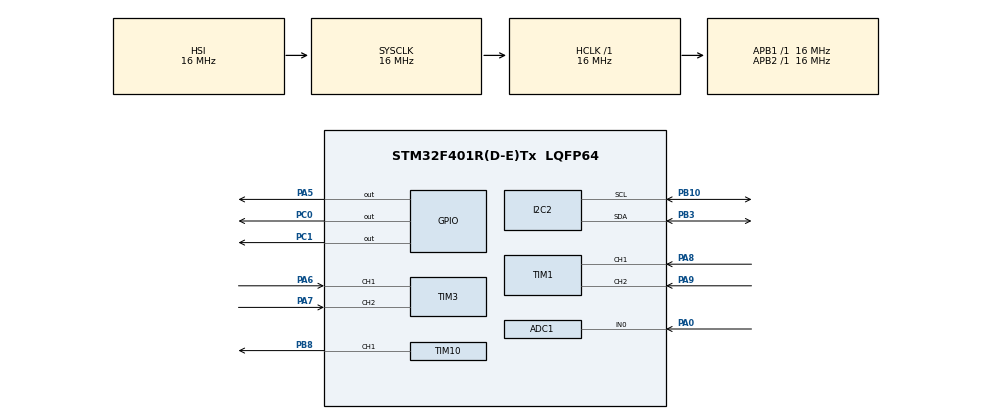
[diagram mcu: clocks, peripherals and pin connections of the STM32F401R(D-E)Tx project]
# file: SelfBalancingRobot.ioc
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Mcu.Family=STM32F4
TIM10.Prescaler=14
Dma.ADC1.0.Instance=DMA2_Stream0
RCC.CortexFreq_Value=16000000
ADC1.Rank-0\#ChannelRegularConversion=1
PB10.Mode=I2C
TIM11.Prescaler=9
PC0.Signal=GPIO_Output
ProjectManager.StackSize=0x400
PA0-WKUP.Signal=ADCx_IN0
VP_TIM11_VS_ClockSourceINT.Mode=Enable_Timer
Dma.ADC1.0.PeriphDataAlignment=DMA_PDATAALIGN_HALFWORD
SH.S_TIM1_CH1.0=TIM1_CH1,Encoder_Interface
ProjectManager.TargetToolchain=STM32CubeIDE
Dma.ADC1.0.Mode=DMA_CIRCULAR
ADC1.Resolution=ADC_RESOLUTION_8B
Dma.ADC1.0.Priority=DMA_PRIORITY_LOW
PA9.Signal=S_TIM1_CH2
VP_TIM10_VS_ClockSourceINT.Mode=Enable_Timer
Dma.ADC1.0.Direction=DMA_PERIPH_TO_MEMORY
NVIC.DMA2_Stream0_IRQn=true\:0\:0\:false\:false\:true\:false\:true
RCC.LSE_VALUE=32768
Dma.ADC1.0.MemDataAlignment=DMA_MDATAALIGN_HALFWORD
RCC.AHBFreq_Value=16000000
PB10.Signal=I2C2_SCL
PA5.Signal=GPIO_Output
ADC1.Channel-0\#ChannelRegularConversion=ADC_CHANNEL_0
SH.S_TIM3_CH2.0=TIM3_CH2,Encoder_Interface
NVIC.TIM1_TRG_COM_TIM11_IRQn=true\:0\:0\:false\:false\:true\:true\:true
RCC.HSE_VALUE=25000000
PB3.Mode=I2C
board=custom
RCC.VCOOutputFreq_Value=192000000
TIM10.Channel=TIM_CHANNEL_1
TIM11.Period=15999
TIM10.Period=99
RCC.APB2Freq_Value=16000000
SH.S_TIM1_CH2.0=TIM1_CH2,Encoder_Interface
Dma.ADC1.0.PeriphInc=DMA_PINC_DISABLE
PA8.Signal=S_TIM1_CH1
SH.ADCx_IN0.0=ADC1_IN0,IN0
SH.S_TIM3_CH1.0=TIM3_CH1,Encoder_Interface
ADC1.DMAContinuousRequests=ENABLE
Mcu.Name=STM32F401R(D-E)Tx
ADC1.SamplingTime-0\#ChannelRegularConversion=ADC_SAMPLETIME_3CYCLES
PB3.Signal=I2C2_SDA
RCC.SYSCLKFreq_VALUE=16000000
Mcu.Package=LQFP64
PA6.Signal=S_TIM3_CH1
ADC1.master=1
SH.S_TIM10_CH1.0=TIM10_CH1,PWM Generation1 CH1
Dma.ADC1.0.MemInc=DMA_MINC_ENABLE
ProjectManager.HeapSize=0x200
RCC.HSI_VALUE=16000000
NVIC.PriorityGroup=NVIC_PRIORITYGROUP_4
ADC1.NbrOfConversionFlag=1
PB8.Signal=S_TIM10_CH1
Dma.ADC1.0.FIFOMode=DMA_FIFOMODE_DISABLE
Dma.Request0=ADC1
RCC.APB1Freq_Value=16000000
I2C2.I2C_Mode=I2C_Fast
ADC1.ClockPrescaler=ADC_CLOCK_SYNC_PCLK_DIV2
PC1.Signal=GPIO_Output
PA7.Signal=S_TIM3_CH2

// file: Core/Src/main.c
/* USER CODE BEGIN Header */
/**
  ******************************************************************************
  * @file           : main.c
  * @brief          : Main program body
  ******************************************************************************
  * @attention
  *
  * <h2><center>&copy; Copyright (c) 2021 STMicroelectronics.
  * All rights reserved.</center></h2>
  *
  * This software component is licensed by ST under BSD 3-Clause license,
  * the "License"; You may not use this file except in compliance with the
  * License. You may obtain a copy of the License at:
  *                        opensource.org/licenses/BSD-3-Clause
  *
  ******************************************************************************
  */
/* USER CODE END Header */
#include "tim.h"
#include "main.h"
#include "i2c.h"
#include "gpio.h"
#include "mpu6050.h"
#include "adc.h"
#include "dma.h"

void SystemClock_Config(void);

int main(void)
{

  /* MCU Configuration--------------------------------------------------------*/

  /* Reset of all peripherals, Initializes the Flash interface and the Systick. */
  HAL_Init();

  /* Configure the system clock */
  SystemClock_Config();

  /* Initialize all configured peripherals */
  MX_GPIO_Init();
  MX_DMA_Init();
  MX_ADC1_Init();
  MX_I2C2_Init();
  MX_TIM1_Init();
  MX_TIM3_Init();
  MX_TIM10_Init();
  MX_TIM11_Init();
  /* USER CODE BEGIN 2 */
	int8_t mpu_ready;
	do {
		mpu_ready = MPU6050_init();
		HAL_Delay(1000);
	} while (mpu_ready == MPU6050_ERR);
//	HAL_GPIO_WritePin(GPIOA, GPIO_PIN_5, GPIO_PIN_SET);
//	set_Gyro_offset(77, -93, -72);
	set_Gyro_offset(82, -101, -76); //Altro MPU
//	set_Gyro_offset(99, 8, 40);

	HAL_GPIO_WritePin(GPIOA, GPIO_PIN_5, GPIO_PIN_RESET);
	//insert_mpu_in_buffer(mpu);

	HAL_TIM_PWM_Start(&htim10, TIM_CHANNEL_1);
	HAL_TIM_Base_Start_IT(&htim11);
  /* USER CODE END 2 */

  /* Infinite loop */
  while (1)
  {

  }
}

void SystemClock_Config(void)
{
  RCC_OscInitTypeDef RCC_OscInitStruct = {0};
  RCC_ClkInitTypeDef RCC_ClkInitStruct = {0};

  /** Configure the main internal regulator output voltage
  */
  __HAL_RCC_PWR_CLK_ENABLE();
  __HAL_PWR_VOLTAGESCALING_CONFIG(PWR_REGULATOR_VOLTAGE_SCALE2);
  /** Initializes the RCC Oscillators according to the specified parameters
  * in the RCC_OscInitTypeDef structure.
  */
  RCC_OscInitStruct.OscillatorType = RCC_OSCILLATORTYPE_HSI;
  RCC_OscInitStruct.HSIState = RCC_HSI_ON;
  RCC_OscInitStruct.HSICalibrationValue = RCC_HSICALIBRATION_DEFAULT;
  RCC_OscInitStruct.PLL.PLLState = RCC_PLL_NONE;
  if (HAL_RCC_OscConfig(&RCC_OscInitStruct) != HAL_OK)
  {
    Error_Handler();
  }
  /** Initializes the CPU, AHB and APB buses clocks
  */
  RCC_ClkInitStruct.ClockType = RCC_CLOCKTYPE_HCLK|RCC_CLOCKTYPE_SYSCLK
                              |RCC_CLOCKTYPE_PCLK1|RCC_CLOCKTYPE_PCLK2;
  RCC_ClkInitStruct.SYSCLKSource = RCC_SYSCLKSOURCE_HSI;
  RCC_ClkInitStruct.AHBCLKDivider = RCC_SYSCLK_DIV1;
  RCC_ClkInitStruct.APB1CLKDivider = RCC_HCLK_DIV1;
  RCC_ClkInitStruct.APB2CLKDivider = RCC_HCLK_DIV1;

  if (HAL_RCC_ClockConfig(&RCC_ClkInitStruct, FLASH_LATENCY_0) != HAL_OK)
  {
    Error_Handler();
  }
}

void Error_Handler(void)
{
  __disable_irq();
  while (1)
  {
  }
}

/************************ (C) COPYRIGHT STMicroelectronics *****END OF FILE****/
